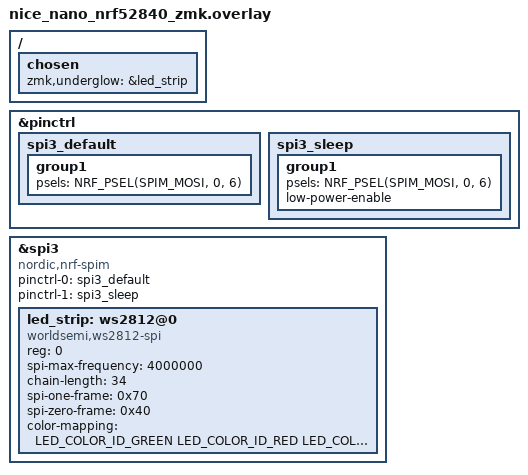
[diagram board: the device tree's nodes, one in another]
/*
 * Butterfly34 + Nice!Nano V2 (nice_nano//zmk) 专用 RGB 底灯配置
 *
 * 仅定义 WS2812 灯带的硬件连接（SPI3 / P0.06），与按键矩阵无关。
 * 需在 butterfly34.conf 中启用 CONFIG_ZMK_RGB_UNDERGLOW=y 后才会生效。
 * Zephyr 4.1 起须使用此文件名，旧名 nice_nano.overlay 不会被加载。
 */

#include <dt-bindings/led/led.h>

&pinctrl {
    spi3_default: spi3_default {
        group1 {
            psels = <NRF_PSEL(SPIM_MOSI, 0, 6)>;
        };
    };

    spi3_sleep: spi3_sleep {
        group1 {
            psels = <NRF_PSEL(SPIM_MOSI, 0, 6)>;
            low-power-enable;
        };
    };
};

&spi3 {
    compatible = "nordic,nrf-spim";
    status = "okay";

    pinctrl-0 = <&spi3_default>;
    pinctrl-1 = <&spi3_sleep>;
    pinctrl-names = "default", "sleep";

    led_strip: ws2812@0 {
        compatible = "worldsemi,ws2812-spi";

        /* SPI */
        reg = <0>; /* ignored, but necessary for SPI bindings */
        spi-max-frequency = <4000000>;

        /* WS2812 */
        chain-length = <34>; /* arbitrary; change at will */
        spi-one-frame = <0x70>;
        spi-zero-frame = <0x40>;

        color-mapping = <LED_COLOR_ID_GREEN LED_COLOR_ID_RED LED_COLOR_ID_BLUE>;
    };
};

/ {
    chosen {
        zmk,underglow = &led_strip;
    };
};
